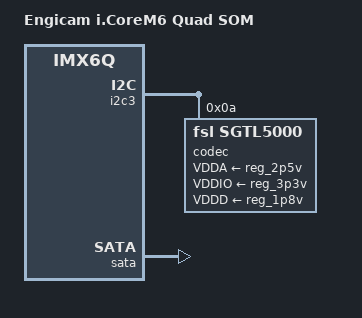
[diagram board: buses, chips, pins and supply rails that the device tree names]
/*
 * Copyright (C) 2015 Amarula Solutions B.V.
 *
 * This file is dual-licensed: you can use it either under the terms
 * of the GPL or the X11 license, at your option. Note that this dual
 * licensing only applies to this file, and not this project as a
 * whole.
 *
 *  a) This file is free software; you can redistribute it and/or
 *     modify it under the terms of the GNU General Public License
 *     version 2 as published by the Free Software Foundation.
 *
 *     This file is distributed in the hope that it will be useful
 *     but WITHOUT ANY WARRANTY; without even the implied warranty of
 *     MERCHANTABILITY or FITNESS FOR A PARTICULAR PURPOSE.  See the
 *     GNU General Public License for more details.
 *
 * Or, alternatively
 *
 *  b) Permission is hereby granted, free of charge, to any person
 *     obtaining a copy of this software and associated documentation
 *     files (the "Software"), to deal in the Software without
 *     restriction, including without limitation the rights to use
 *     copy, modify, merge, publish, distribute, sublicense, and/or
 *     sell copies of the Software, and to permit persons to whom the
 *     Software is furnished to do so, subject to the following
 *     conditions:
 *
 *     The above copyright notice and this permission notice shall be
 *     included in all copies or substantial portions of the Software.
 *
 *     THE SOFTWARE IS PROVIDED , WITHOUT WARRANTY OF ANY KIND
 *     EXPRESS OR IMPLIED, INCLUDING BUT NOT LIMITED TO THE WARRANTIES
 *     OF MERCHANTABILITY, FITNESS FOR A PARTICULAR PURPOSE AND
 *     NONINFRINGEMENT. IN NO EVENT SHALL THE AUTHORS OR COPYRIGHT
 *     HOLDERS BE LIABLE FOR ANY CLAIM, DAMAGES OR OTHER LIABILITY
 *     WHETHER IN AN ACTION OF CONTRACT, TORT OR OTHERWISE, ARISING
 *     FROM, OUT OF OR IN CONNECTION WITH THE SOFTWARE OR THE USE OR
 *     OTHER DEALINGS IN THE SOFTWARE.
 */

/dts-v1/;

#include "imx6q.dtsi"
#include "imx6qdl-icore-rqs.dtsi"

/ {
	model = "Engicam i.CoreM6 Quad SOM";
	compatible = "engicam,imx6-icore-rqs", "fsl,imx6q";

	sound {
		compatible = "fsl,imx-audio-sgtl5000";
		model = "imx-audio-sgtl5000";
		ssi-controller = <&ssi1>;
		audio-codec = <&codec>;
		audio-routing =
			"MIC_IN", "Mic Jack",
			"Mic Jack", "Mic Bias",
			"Headphone Jack", "HP_OUT";
		mux-int-port = <1>;
		mux-ext-port = <4>;
	};
};

&i2c3 {
	codec: sgtl5000@0a {
		compatible = "fsl,sgtl5000";
		reg = <0x0a>;
		clocks = <&clks IMX6QDL_CLK_CKO>;
		VDDA-supply = <&reg_2p5v>;
		VDDIO-supply = <&reg_3p3v>;
		VDDD-supply = <&reg_1p8v>;
	};
};

&sata {
	status = "okay";
};
